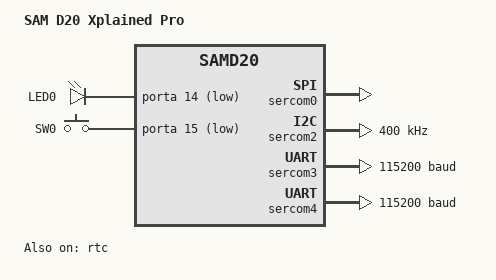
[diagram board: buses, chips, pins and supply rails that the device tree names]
/*
 * Copyright (c) 2018 Sean Nyekjaer
 * # Copyright (c) 2024-2025 Gerson Fernando Budke <nandojve@gmail.com>
 *
 * SPDX-License-Identifier: Apache-2.0
 */

/dts-v1/;
#include <freq.h>
#include <atmel/samd20.dtsi>
#include <atmel/samx2xx18.dtsi>
#include "samd20_xpro-pinctrl.dtsi"
#include <zephyr/dt-bindings/input/input-event-codes.h>

/ {
	model = "SAM D20 Xplained Pro";
	compatible = "samd20,xpro", "atmel,samd20j18", "atmel,samd20";

	chosen {
		zephyr,console = &sercom3;
		zephyr,shell-uart = &sercom3;
		zephyr,sram = &sram0;
		zephyr,flash = &flash0;
	};

	/* These aliases are provided for compatibility with samples */
	aliases {
		led0 = &yellow_led;
		sw0 = &user_button;
		i2c-0 = &sercom2;
	};

	leds {
		compatible = "gpio-leds";

		yellow_led: led_0 {
			gpios = <&porta 14 GPIO_ACTIVE_LOW>;
			label = "LED0";
		};
	};

	buttons {
		compatible = "gpio-keys";

		user_button: button_0 {
			gpios = <&porta 15 (GPIO_PULL_UP | GPIO_ACTIVE_LOW)>;
			label = "SW0";
			zephyr,code = <INPUT_KEY_0>;
		};
	};
};

&cpu0 {
	clock-frequency = <DT_FREQ_M(48)>;
};

&rtc {
	status = "okay";
	counter-mode = "clock";
	prescaler = <1024>;
};

&sercom0 {
	status = "okay";
	compatible = "atmel,sam0-spi";
	dipo = <0>;
	dopo = <1>;
	#address-cells = <1>;
	#size-cells = <0>;
	cs-gpios = <&porta 5 GPIO_ACTIVE_LOW>;

	pinctrl-0 = <&sercom0_spi_default>;
	pinctrl-names = "default";
};

&sercom2 {
	status = "okay";
	compatible = "atmel,sam0-i2c";
	clock-frequency = <I2C_BITRATE_FAST>;
	#address-cells = <1>;
	#size-cells = <0>;

	pinctrl-0 = <&sercom2_i2c_default>;
	pinctrl-names = "default";
};

&sercom3 {
	status = "okay";
	compatible = "atmel,sam0-uart";
	current-speed = <115200>;
	rxpo = <3>;
	txpo = <1>;

	pinctrl-0 = <&sercom3_uart_default>;
	pinctrl-names = "default";
};

&sercom4 {
	status = "okay";
	compatible = "atmel,sam0-uart";
	current-speed = <115200>;
	rxpo = <1>;
	txpo = <0>;

	pinctrl-0 = <&sercom4_uart_default>;
	pinctrl-names = "default";
};

&flash0 {
	partitions {
		compatible = "fixed-partitions";
		#address-cells = <1>;
		#size-cells = <1>;

		/*
		 * The final 16 KiB is reserved for the application.
		 * Storage partition will be used by FCB/LittleFS/NVS
		 * if enabled.
		 */
		storage_partition: partition@3c000 {
			label = "storage";
			reg = <0x0003c000 0x00004000>;
		};
	};
};
